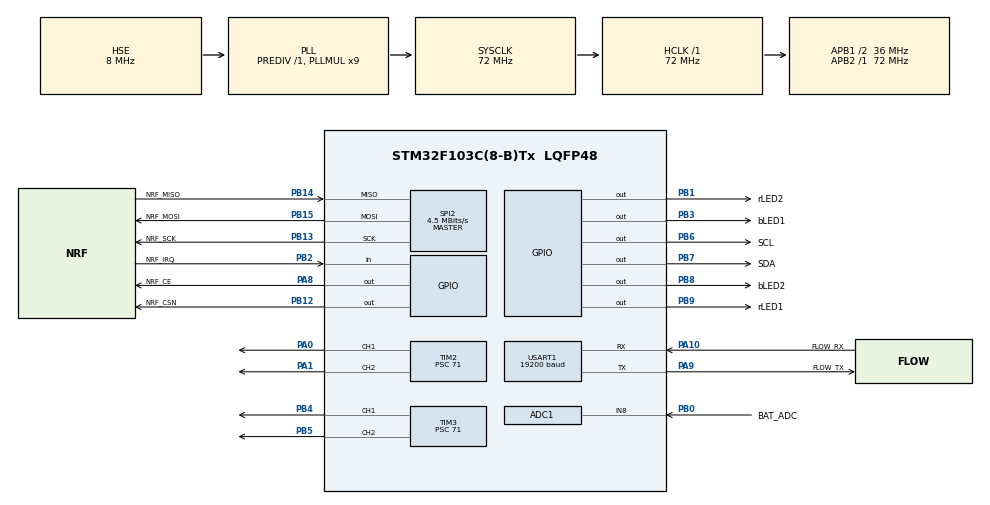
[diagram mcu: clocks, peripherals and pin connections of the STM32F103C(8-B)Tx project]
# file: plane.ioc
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ADC1.Channel-0\#ChannelRegularConversion=ADC_CHANNEL_8
ADC1.Channel-1\#ChannelRegularConversion=ADC_CHANNEL_VREFINT
ADC1.ContinuousConvMode=ENABLE
ADC1.NbrOfConversion=2
ADC1.NbrOfConversionFlag=1
ADC1.Rank-0\#ChannelRegularConversion=1
ADC1.Rank-1\#ChannelRegularConversion=2
ADC1.SamplingTime-0\#ChannelRegularConversion=ADC_SAMPLETIME_55CYCLES_5
ADC1.SamplingTime-1\#ChannelRegularConversion=ADC_SAMPLETIME_55CYCLES_5
ADC1.master=1
Dma.ADC1.0.Direction=DMA_PERIPH_TO_MEMORY
Dma.ADC1.0.Instance=DMA1_Channel1
Dma.ADC1.0.MemDataAlignment=DMA_MDATAALIGN_HALFWORD
Dma.ADC1.0.MemInc=DMA_MINC_ENABLE
Dma.ADC1.0.Mode=DMA_CIRCULAR
Dma.ADC1.0.PeriphDataAlignment=DMA_PDATAALIGN_HALFWORD
Dma.ADC1.0.PeriphInc=DMA_PINC_DISABLE
Dma.ADC1.0.Priority=DMA_PRIORITY_LOW
Dma.Request0=ADC1
FREERTOS.Tasks01=defaultTask,0,128,StartDefaultTask,Default,NULL,Dynamic,NULL,NULL
Mcu.Family=STM32F1
Mcu.Name=STM32F103C(8-B)Tx
Mcu.Package=LQFP48
NVIC.DMA1_Channel1_IRQn=true\:5\:0\:false\:false\:true\:true\:false\:true\:true
NVIC.PriorityGroup=NVIC_PRIORITYGROUP_4
NVIC.TIM4_IRQn=true\:15\:0\:false\:false\:true\:false\:false\:true\:true
NVIC.TimeBase=TIM4_IRQn
NVIC.TimeBaseIP=TIM4
NVIC.USART1_IRQn=true\:5\:0\:false\:false\:true\:true\:true\:true\:true
PA0-WKUP.GPIO_Speed=GPIO_SPEED_FREQ_HIGH
PA0-WKUP.Signal=S_TIM2_CH1_ETR
PA1.GPIO_Speed=GPIO_SPEED_FREQ_HIGH
PA1.Signal=S_TIM2_CH2
PA10.GPIO_Label=FLOW_RX
PA10.GPIO_PuPd=GPIO_PULLUP
PA10.Mode=Asynchronous
PA10.Signal=USART1_RX
PA13.Mode=Serial_Wire
PA13.Signal=SYS_JTMS-SWDIO
PA14.Mode=Serial_Wire
PA14.Signal=SYS_JTCK-SWCLK
PA8.GPIO_Label=NRF_CE
PA8.GPIO_Speed=GPIO_SPEED_FREQ_HIGH
PA8.PinState=GPIO_PIN_SET
PA8.Signal=GPIO_Output
PA9.GPIO_Label=FLOW_TX
PA9.Mode=Asynchronous
PA9.Signal=USART1_TX
PB0.GPIO_Label=BAT_ADC
PB0.Signal=ADCx_IN8
PB1.GPIO_Label=rLED2
PB1.Signal=GPIO_Output
PB12.GPIO_Label=NRF_CSN
PB12.GPIO_Speed=GPIO_SPEED_FREQ_HIGH
PB12.PinState=GPIO_PIN_SET
PB12.Signal=GPIO_Output
PB13.GPIO_Label=NRF_SCK
PB13.Mode=Full_Duplex_Master
PB13.Signal=SPI2_SCK
PB14.GPIO_Label=NRF_MISO
PB14.GPIO_PuPd=GPIO_PULLUP
PB14.Mode=Full_Duplex_Master
PB14.Signal=SPI2_MISO
PB15.GPIO_Label=NRF_MOSI
PB15.Mode=Full_Duplex_Master
PB15.Signal=SPI2_MOSI
PB2.GPIO_Label=NRF_IRQ
PB2.GPIO_PuPd=GPIO_PULLUP
PB2.Signal=GPIO_Input
PB3.GPIO_Label=bLED1
PB3.Signal=GPIO_Output
PB4.GPIO_Speed=GPIO_SPEED_FREQ_HIGH
PB4.Signal=S_TIM3_CH1
PB5.GPIO_Speed=GPIO_SPEED_FREQ_HIGH
PB5.Signal=S_TIM3_CH2
PB6.GPIO_Label=SCL
PB6.GPIO_ModeDefaultOutputPP=GPIO_MODE_OUTPUT_OD
PB6.GPIO_PuPd=GPIO_NOPULL
PB6.GPIO_Speed=GPIO_SPEED_FREQ_HIGH
PB6.Signal=GPIO_Output
PB7.GPIO_Label=SDA
PB7.GPIO_ModeDefaultOutputPP=GPIO_MODE_OUTPUT_OD
PB7.GPIO_PuPd=GPIO_NOPULL
PB7.GPIO_Speed=GPIO_SPEED_FREQ_HIGH
PB7.Signal=GPIO_Output
PB8.GPIO_Label=bLED2
PB8.Signal=GPIO_Output
PB9.GPIO_Label=rLED1
PB9.Signal=GPIO_Output
PD0-OSC_IN.Mode=HSE-External-Oscillator
PD0-OSC_IN.Signal=RCC_OSC_IN
PD1-OSC_OUT.Mode=HSE-External-Oscillator
PD1-OSC_OUT.Signal=RCC_OSC_OUT
ProjectManager.HeapSize=0x200
ProjectManager.StackSize=0x400
ProjectManager.TargetToolchain=CMake
RCC.ADCPresc=RCC_ADCPCLK2_DIV6
RCC.AHBFreq_Value=72000000
RCC.APB1CLKDivider=RCC_HCLK_DIV2
RCC.APB1Freq_Value=36000000
RCC.APB1TimFreq_Value=72000000
RCC.APB2Freq_Value=72000000
RCC.APB2TimFreq_Value=72000000
RCC.HCLKFreq_Value=72000000
RCC.PLLMUL=RCC_PLL_MUL9
RCC.PLLSourceVirtual=RCC_PLLSOURCE_HSE
RCC.SYSCLKFreq_VALUE=72000000
RCC.SYSCLKSource=RCC_SYSCLKSOURCE_PLLCLK
RCC.USBFreq_Value=72000000
SH.ADCx_IN8.0=ADC1_IN8,IN8
SH.S_TIM2_CH1_ETR.0=TIM2_CH1,PWM Generation1 CH1
SH.S_TIM2_CH2.0=TIM2_CH2,PWM Generation2 CH2
SH.S_TIM3_CH1.0=TIM3_CH1,PWM Generation1 CH1
SH.S_TIM3_CH2.0=TIM3_CH2,PWM Generation2 CH2
SPI2.BaudRatePrescaler=SPI_BAUDRATEPRESCALER_8
SPI2.CalculateBaudRate=4.5 MBits/s
SPI2.Direction=SPI_DIRECTION_2LINES
SPI2.Mode=SPI_MODE_MASTER
SPI2.VirtualType=VM_MASTER
TIM2.AutoReloadPreload=TIM_AUTORELOAD_PRELOAD_ENABLE
TIM2.Channel-PWM\ Generation1\ CH1=TIM_CHANNEL_1
TIM2.Channel-PWM\ Generation2\ CH2=TIM_CHANNEL_2
TIM2.Period=2499
TIM2.Prescaler=71
TIM2.Pulse-PWM\ Generation1\ CH1=1000
TIM2.Pulse-PWM\ Generation2\ CH2=1000
TIM3.AutoReloadPreload=TIM_AUTORELOAD_PRELOAD_ENABLE
TIM3.Channel-PWM\ Generation1\ CH1=TIM_CHANNEL_1
TIM3.Channel-PWM\ Generation2\ CH2=TIM_CHANNEL_2
TIM3.Period=2499
TIM3.Prescaler=71
TIM3.Pulse-PWM\ Generation1\ CH1=1000
TIM3.Pulse-PWM\ Generation2\ CH2=1000
USART1.BaudRate=19200
USART1.VirtualMode=VM_ASYNC
VP_ADC1_Vref_Input.Mode=IN-Vrefint
VP_FREERTOS_VS_CMSIS_V1.Mode=CMSIS_V1
VP_SYS_VS_tim4.Mode=TIM4
VP_TIM2_VS_ClockSourceINT.Mode=Internal
VP_TIM3_VS_ClockSourceINT.Mode=Internal
board=custom

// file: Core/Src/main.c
/* USER CODE BEGIN Header */
/**
  ******************************************************************************
  * @file           : main.c
  * @brief          : Main program body
  ******************************************************************************
  * @attention
  *
  * Copyright (c) 2026 STMicroelectronics.
  * All rights reserved.
  *
  * This software is licensed under terms that can be found in the LICENSE file
  * in the root directory of this software component.
  * If no LICENSE file comes with this software, it is provided AS-IS.
  *
  ******************************************************************************
  */
/* USER CODE END Header */
#include "main.h"
#include "cmsis_os.h"
#include "adc.h"
#include "dma.h"
#include "motor.h"
#include "spi.h"
#include "tim.h"
#include "usart.h"
#include "gpio.h"

/* USER CODE BEGIN Includes */
#include "headfile.h"
/* USER CODE END Includes */

void SystemClock_Config(void);
void MX_FREERTOS_Init(void);

int main(void)
{

  /* MCU Configuration--------------------------------------------------------*/

  /* Reset of all peripherals, Initializes the Flash interface and the Systick. */
  HAL_Init();

  /* Configure the system clock */
  SystemClock_Config();

  /* Initialize all configured peripherals */
  MX_GPIO_Init();
  MX_DMA_Init();
  MX_TIM2_Init();
  MX_TIM3_Init();
  MX_USART1_UART_Init();
  MX_SPI2_Init();
  MX_ADC1_Init();
  /* USER CODE BEGIN 2 */
  System_Init();
  /* USER CODE END 2 */

  /* Call init function for freertos objects (in cmsis_os2.c) */
  MX_FREERTOS_Init();

  /* Start scheduler */
  osKernelStart();

  /* We should never get here as control is now taken by the scheduler */

  /* Infinite loop */
  while (1)
  {

  }
}

void SystemClock_Config(void)
{
  RCC_OscInitTypeDef RCC_OscInitStruct = {0};
  RCC_ClkInitTypeDef RCC_ClkInitStruct = {0};
  RCC_PeriphCLKInitTypeDef PeriphClkInit = {0};

  /** Initializes the RCC Oscillators according to the specified parameters
  * in the RCC_OscInitTypeDef structure.
  */
  RCC_OscInitStruct.OscillatorType = RCC_OSCILLATORTYPE_HSE;
  RCC_OscInitStruct.HSEState = RCC_HSE_ON;
  RCC_OscInitStruct.HSEPredivValue = RCC_HSE_PREDIV_DIV1;
  RCC_OscInitStruct.HSIState = RCC_HSI_ON;
  RCC_OscInitStruct.PLL.PLLState = RCC_PLL_ON;
  RCC_OscInitStruct.PLL.PLLSource = RCC_PLLSOURCE_HSE;
  RCC_OscInitStruct.PLL.PLLMUL = RCC_PLL_MUL9;
  if (HAL_RCC_OscConfig(&RCC_OscInitStruct) != HAL_OK)
  {
    Error_Handler();
  }

  /** Initializes the CPU, AHB and APB buses clocks
  */
  RCC_ClkInitStruct.ClockType = RCC_CLOCKTYPE_HCLK|RCC_CLOCKTYPE_SYSCLK
                              |RCC_CLOCKTYPE_PCLK1|RCC_CLOCKTYPE_PCLK2;
  RCC_ClkInitStruct.SYSCLKSource = RCC_SYSCLKSOURCE_PLLCLK;
  RCC_ClkInitStruct.AHBCLKDivider = RCC_SYSCLK_DIV1;
  RCC_ClkInitStruct.APB1CLKDivider = RCC_HCLK_DIV2;
  RCC_ClkInitStruct.APB2CLKDivider = RCC_HCLK_DIV1;

  if (HAL_RCC_ClockConfig(&RCC_ClkInitStruct, FLASH_LATENCY_2) != HAL_OK)
  {
    Error_Handler();
  }
  PeriphClkInit.PeriphClockSelection = RCC_PERIPHCLK_ADC;
  PeriphClkInit.AdcClockSelection = RCC_ADCPCLK2_DIV6;
  if (HAL_RCCEx_PeriphCLKConfig(&PeriphClkInit) != HAL_OK)
  {
    Error_Handler();
  }
}

void HAL_TIM_PeriodElapsedCallback(TIM_HandleTypeDef *htim)
{
  if (htim->Instance == TIM4)
  {
    HAL_IncTick();
  }
}

void Error_Handler(void)
{
  __disable_irq();
  while (1)
  {
  }
}

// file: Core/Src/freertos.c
/* USER CODE BEGIN Header */
/**
  ******************************************************************************
  * File Name          : freertos.c
  * Description        : Code for freertos applications
  ******************************************************************************
  * @attention
  *
  * Copyright (c) 2026 STMicroelectronics.
  * All rights reserved.
  *
  * This software is licensed under terms that can be found in the LICENSE file
  * in the root directory of this software component.
  * If no LICENSE file comes with this software, it is provided AS-IS.
  *
  ******************************************************************************
  */
/* USER CODE END Header */

#include "FreeRTOS.h"
#include "task.h"
#include "main.h"
#include "cmsis_os.h"

/* USER CODE BEGIN Includes */
#include "task.h"
/* USER CODE END Includes */

osThreadId controlTaskHandle;
// osThreadId imuTaskHandle;
osThreadId commTaskHandle;
osThreadId otherTaskHandle;

void StartDefaultTask(void const * argument);

void MX_FREERTOS_Init(void); /* (MISRA C 2004 rule 8.1) */

/* GetIdleTaskMemory prototype (linked to static allocation support) */
void vApplicationGetIdleTaskMemory( StaticTask_t **ppxIdleTaskTCBBuffer, StackType_t **ppxIdleTaskStackBuffer, uint32_t *pulIdleTaskStackSize );

/* USER CODE BEGIN GET_IDLE_TASK_MEMORY */
static StaticTask_t xIdleTaskTCBBuffer;
static StackType_t xIdleStack[configMINIMAL_STACK_SIZE];

void vApplicationGetIdleTaskMemory( StaticTask_t **ppxIdleTaskTCBBuffer, StackType_t **ppxIdleTaskStackBuffer, uint32_t *pulIdleTaskStackSize )
{
  *ppxIdleTaskTCBBuffer = &xIdleTaskTCBBuffer;
  *ppxIdleTaskStackBuffer = &xIdleStack[0];
  *pulIdleTaskStackSize = configMINIMAL_STACK_SIZE;
  /* place for user code */
}
/* USER CODE END GET_IDLE_TASK_MEMORY */

void MX_FREERTOS_Init(void) {

  /* Create the thread(s) */
  /* definition and creation of defaultTask */

  // osThreadDef(imuTask, StartControlTask, osPriorityHigh, 0, 128);
  // imuTaskHandle = osThreadCreate(osThread(imuTask), NULL);

  osThreadDef(controlTask, StartControlTask, osPriorityHigh, 0, 256);
  controlTaskHandle = osThreadCreate(osThread(controlTask), NULL);

  osThreadDef(commTask, StartCommTask, osPriorityHigh, 0, 128);
  commTaskHandle = osThreadCreate(osThread(commTask), NULL);

  osThreadDef(otherTask, StartOtherTask, osPriorityAboveNormal, 0, 128);
  otherTaskHandle = osThreadCreate(osThread(otherTask), NULL);

}

void StartDefaultTask(void const * argument)
{
  for(;;)
  {
    osDelay(1);
  }
}
